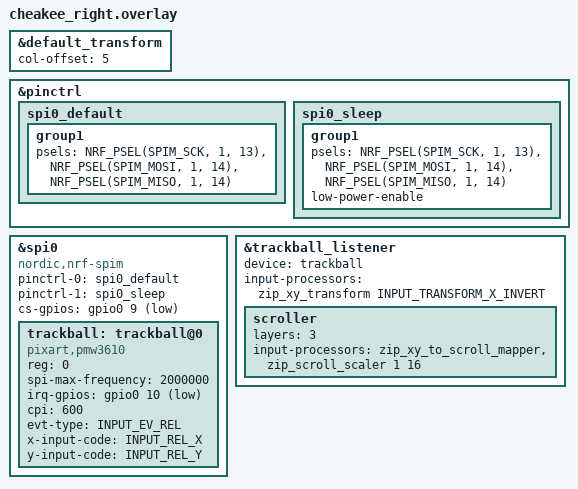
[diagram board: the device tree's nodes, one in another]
#include <input/processors.dtsi>
#include <dt-bindings/zmk/input_transform.h>
#include "cheakee.dtsi"

&default_transform {
    col-offset = <5>;
};

&pinctrl {
    spi0_default: spi0_default {
        group1 {
            psels = <NRF_PSEL(SPIM_SCK, 1, 13)>,
                <NRF_PSEL(SPIM_MOSI, 1, 14)>,
                <NRF_PSEL(SPIM_MISO, 1, 14)>;
        };
    };

    spi0_sleep: spi0_sleep {
        group1 {
            psels = <NRF_PSEL(SPIM_SCK, 1, 13)>,
                <NRF_PSEL(SPIM_MOSI, 1, 14)>,
                <NRF_PSEL(SPIM_MISO, 1, 14)>;
            low-power-enable;
        };
    };
};

&spi0 {
    status = "okay";
    compatible = "nordic,nrf-spim";
    pinctrl-0 = <&spi0_default>;
    pinctrl-1 = <&spi0_sleep>;
    pinctrl-names = "default", "sleep";
    cs-gpios = <&gpio0 9 GPIO_ACTIVE_LOW>;

    // https://github.com/zmkfirmware/zephyr/blob/v3.5.0%2Bzmk-fixes/include/zephyr/dt-bindings/input/input-event-codes.h#L245
    trackball: trackball@0 {
        status = "okay";
        compatible = "pixart,pmw3610";
        reg = <0>;
        spi-max-frequency = <2000000>;
        irq-gpios = <&gpio0 10 (GPIO_ACTIVE_LOW | GPIO_PULL_UP)>;
        cpi = <600>;
        evt-type = <INPUT_EV_REL>;
        x-input-code = <INPUT_REL_X>;
        y-input-code = <INPUT_REL_Y>;
    };
};

&trackball_listener {
    status = "okay";
    device = <&trackball>;
    input-processors = <&zip_xy_transform INPUT_TRANSFORM_X_INVERT>;

    scroller {
        layers = <3>;
        input-processors = <&zip_xy_to_scroll_mapper &zip_scroll_scaler 1 16>;
    };
};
